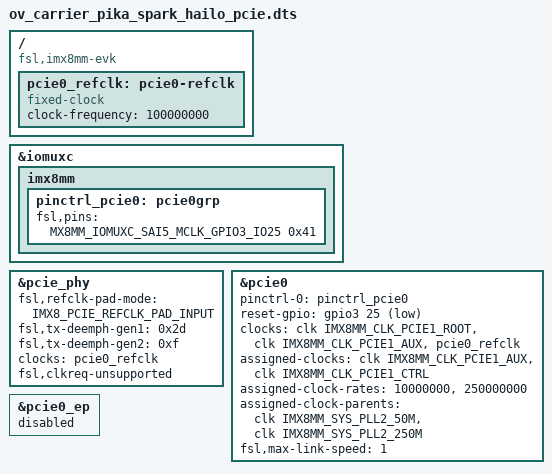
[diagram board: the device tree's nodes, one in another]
/**
 * Portenta-X8 dtb overlay file
 * LXRobotics 2025
 * Enable PCIe x1 for Hailo-8L expansion board
 */

/dts-v1/;
/plugin/;

#include "imx8mm-pinfunc.h"
#include <dt-bindings/clock/imx8mm-clock.h>
#include <dt-bindings/phy/phy-imx8-pcie.h>
#include <dt-bindings/gpio/gpio.h>

/ {
	compatible = "fsl,imx8mm-evk", "fsl,imx8mm";

	/* Pins mux and pad configuration */
	fragment@0 {
		target = <&iomuxc>;
		__overlay__ {
			imx8mm {
				/* Pins PCIe */
				pinctrl_pcie0: pcie0grp {
					fsl,pins = <
						/* PCIE_nRST */
						MX8MM_IOMUXC_SAI5_MCLK_GPIO3_IO25               0x41
						/* PCIE_CLKREQ open drain, pull up */
						/* MX8MM_IOMUXC_I2C4_SCL_PCIE1_CLKREQ_B	0x61 - needs another pin, the one that we use ... */
					>;
				};
			};
		};
	};

	/* PCIe */
	fragment@1{
		target-path = "/";
		__overlay__ {
			pcie0_refclk: pcie0-refclk {
				compatible = "fixed-clock";
				#clock-cells = <0>;
				clock-frequency = <100000000>;
			};
		};
	};

	fragment@2 {
		target = <&pcie_phy>;
		__overlay__ {
			fsl,refclk-pad-mode = <IMX8_PCIE_REFCLK_PAD_INPUT>;
			fsl,tx-deemph-gen1 = <0x2d>;
			fsl,tx-deemph-gen2 = <0xf>;
			clocks = <&pcie0_refclk>;
			clock-names = "ref";
			fsl,clkreq-unsupported;
			status = "okay";
		};
	};

	fragment@3 {
		target = <&pcie0>;
		__overlay__ {
			pinctrl-names = "default";
			pinctrl-0 = <&pinctrl_pcie0>;
			reset-gpio = <&gpio3 25 GPIO_ACTIVE_LOW>;
			clocks = <&clk IMX8MM_CLK_PCIE1_ROOT>,
				<&clk IMX8MM_CLK_PCIE1_AUX>,
				<&pcie0_refclk>;
			clock-names = "pcie", "pcie_aux", "pcie_bus";
			assigned-clocks = <&clk IMX8MM_CLK_PCIE1_AUX>,
				<&clk IMX8MM_CLK_PCIE1_CTRL>;
			assigned-clock-rates = <10000000>, <250000000>;
			assigned-clock-parents = <&clk IMX8MM_SYS_PLL2_50M>,
				<&clk IMX8MM_SYS_PLL2_250M>;
			fsl,max-link-speed = <1>;
			status = "okay";
		};
	};

	fragment@4{
		target = <&pcie0_ep>;
		__overlay__ {
			status = "disabled";
		};
	};
};
